# RL6842_IP_SVD register map
Vendor: Realtek
Registers are 32-bit, read-write, reset 0x0 unless marked. A register's access mark holds for its fields unless they carry their own. Offsets are from the block's base; [hi:lo] are bit positions; lines under a group give offsets from that group; {n}, {i} and the like mark numbered series.

## MEMX
Base 0x4100C600
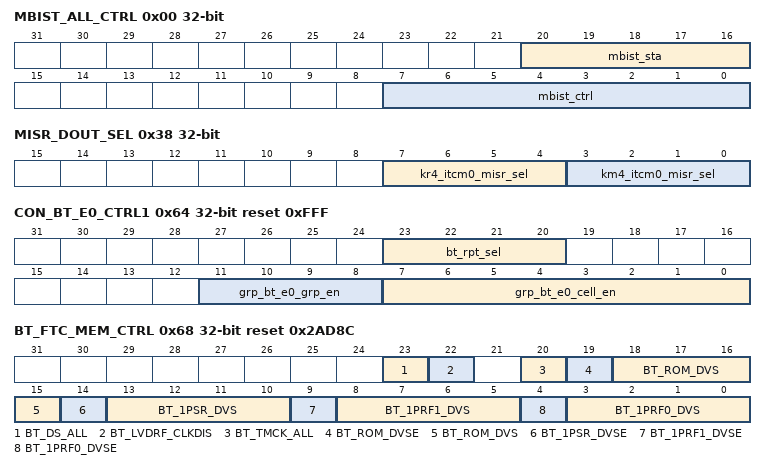
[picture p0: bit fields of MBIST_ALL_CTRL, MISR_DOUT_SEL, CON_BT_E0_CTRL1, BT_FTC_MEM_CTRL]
0x00 MBIST_ALL_CTRL access per field
  [20:16] mbist_sta ro — Total mbist status [16] MBIST DRF_START_PAUSE [17] MBIST NRML_DONE_ALL [18] MBIST NRML_FAIL_ALL [19] MBIST DRF_DONE_ALL [20] MBIST DRF_FAIL_ALL
  [7:0] mbist_ctrl rw — Total mbist control [0] MBIST_CLK_EN_ALL BIS_CLK enable of all system memory groups. [1] MBIST_RSTB_ALL Reset controll mbist circuit of all system memory groups. [3:2]MBIST_MSEL_ALL mbist method selection of all memory groups: 2'b01: enable normal mode mbist 2'b10: enable DRF mode mbist 2'b11: enable normal&DRF mode mbist [4]MBIST_RESUME [5]MBIST_RESUME_PS [6]MBIST_DYN_READ_EN If MBIST_MSEL_ALL[1]=1 & MBIST_DYN_READ_EN=1, run VDDR mode mbist. [7]MBIST_PHYCLK_STOP
0x04 MBIST_DONE_STA0 ro
  [30:0] mbist_done — 30 mbist_group in es003 1 special group bt_e0
0x08 MBIST_START_PAUSE0 ro
  [30:0] mbist_start_pause
0x0C MBIST_NORM_FAIL0 ro
  [31:0] mbist_norm_fail_31_0
0x10 MBIST_NORM_FAIL1 ro
  [31:0] mbist_norm_fail_63_32
0x14 MBIST_NORM_FAIL2 ro
  [23:0] mbist_norm_fail_87_64 — 87 memory block in es003 1 special bt block
0x18 MBIST_DRF_FAIL0 ro
  [31:0] mbist_drf_fail_31_0
0x1C MBIST_DRF_FAIL1 ro
  [31:0] mbist_drf_fail_63_32
0x20 MBIST_DRF_FAIL2 ro
  [23:0] mbist_drf_fail_87_64 — 87 memory block in es003 1 special bt block
0x24 BT_BIST_DONE ro
0x28 BT_BIST_FAIL ro
0x2C BT_BIST_DRF_PASUE ro
  [31:0] bt_bist_drf_pause
0x38 MISR_DOUT_SEL
  [7:4] kr4_itcm0_misr_sel — Used for KR4 itcm rom mbist, select which rom's misr_dataout[63:0] can be read from KR4_ITCM_ROM_MISR_DOUT.
  [3:0] km4_itcm0_misr_sel — Used for KM4 itcm rom mbist, select which rom's misr_dataout[63:0] can be read from KM4_ITCM_ROM_MISR_DOUT.
0x3C MBIST_ROM_MISR0 ro
  [31:0] rom_lspmc_e0_misr_dout_31_0
0x40 MBIST_ROM_MISR1 ro
  [3:0] rom_lspmc_e0_misr_dout_35_32
0x44 MBIST_ROM_MISR2 ro
  [31:0] rom_aonpmc_e0_misr_dout_31_0
0x48 MBIST_ROM_MISR3 ro
  [3:0] rom_aonpmc_e0_misr_dout_35_32
0x4C MBIST_ROM_MISR4 ro
  [31:0] km4_itcm0_rom_misr_dout_31_0
0x50 MBIST_ROM_MISR5 ro
  [31:0] km4_itcm0_rom_misr_dout_63_32
0x54 MBIST_ROM_MISR6 ro
  [31:0] kr4_itcm0_rom_misr_dout_31_0
0x58 MBIST_ROM_MISR7 ro
  [31:0] kr4_itcm0_rom_misr_dout_63_32
0x60 BT_BIST_RPT ro
  [31:0] bt_bist_rpt — bt_rpt_sel 0~3 : read bt_bist_rpt to get BT bist status; bt_rpt_sel 4~15 : read bt_bist_rpt to get BT rom misr_dout;
0x64 CON_BT_E0_CTRL1 reset 0xFFF
  [23:20] bt_rpt_sel — Select which rom's misr_dataout or bist_status of each memory can be read from bt_bist_rpt.
  [11:8] grp_bt_e0_grp_en — Devide all 30 BT memory blocks into 4 groups. grp_bt_e0_grp_en[N]=1 N=0~3: enable mbist of bt_e0 group N.
  [7:0] grp_bt_e0_cell_en — grp_bt_e0_cell_en[M]=1 M=0~7: enable mbist of mem cell M in groups whose grp_bt_e0_grp_en set 1.
0x68 BT_FTC_MEM_CTRL reset 0x2AD8C
  [23] BT_DS_ALL — 1 - All BT memory switch to Deep Sleep mode 0 - Power mode of BT memory are controlled by BTPMC
  [22] BT_LVDRF_CLKDIS
  [20] BT_TMCK_ALL
  [19] BT_ROM_DVSE
  [18:15] BT_ROM_DVS — FSNOU_A_SPNN
  [14] BT_1PSR_DVSE — Not used in Lite
  [13:10] BT_1PSR_DVS — Not used in Lite
  [9] BT_1PRF1_DVSE
  [8:5] BT_1PRF1_DVS — FSNOU_A_SYNL
  [4] BT_1PRF0_DVSE
  [3:0] BT_1PRF0_DVS — FSNOU_A_SYNL
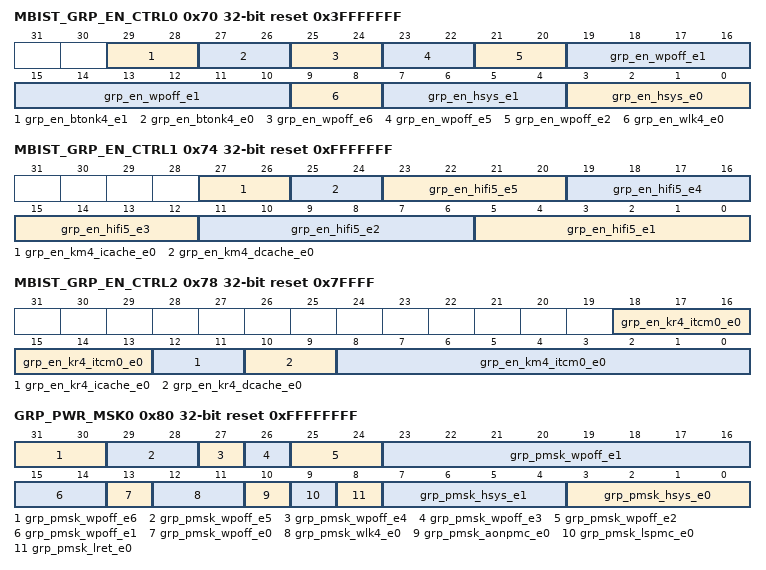
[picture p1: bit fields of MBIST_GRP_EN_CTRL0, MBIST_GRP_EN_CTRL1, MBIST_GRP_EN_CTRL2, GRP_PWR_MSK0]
0x70 MBIST_GRP_EN_CTRL0 reset 0x3FFFFFFF — Used to on-off mbist of a memory group.
  [29:28] grp_en_btonk4_e1
  [27:26] grp_en_btonk4_e0
  [25:24] grp_en_wpoff_e6 — Not used, TPRAM/DPRAM don't need grp_en
  [23:22] grp_en_wpoff_e5 — Not used, TPRAM/DPRAM don't need grp_en
  [21:20] grp_en_wpoff_e2 — Not used, TPRAM/DPRAM don't need grp_en
  [19:10] grp_en_wpoff_e1
  [9:8] grp_en_wlk4_e0
  [7:4] grp_en_hsys_e1
  [3:0] grp_en_hsys_e0
0x74 MBIST_GRP_EN_CTRL1 reset 0xFFFFFFF — Used to on-off mbist in a memory group.
  [27:26] grp_en_km4_icache_e0, [25:24] grp_en_km4_dcache_e0, [23:20] grp_en_hifi5_e5, [19:16] grp_en_hifi5_e4, [15:12] grp_en_hifi5_e3, [11:6] grp_en_hifi5_e2, [5:0] grp_en_hifi5_e1
0x78 MBIST_GRP_EN_CTRL2 reset 0x7FFFF — Used to on-off mbist of memory block in a group.
  [18:13] grp_en_kr4_itcm0_e0, [12:11] grp_en_kr4_icache_e0, [10:9] grp_en_kr4_dcache_e0, [8:0] grp_en_km4_itcm0_e0
0x80 GRP_PWR_MSK0 reset 0xFFFFFFFF
  [31:30] grp_pmsk_wpoff_e6 — WIFI-PMC controlled memory group: bit[N] = 1: power mode of memory block N is controlled by wifi-PMC power signals bit[N] = 0: power port of memory block N is tie0.
  [29:28] grp_pmsk_wpoff_e5 — merged
  [27] grp_pmsk_wpoff_e4 — merged
  [26] grp_pmsk_wpoff_e3 — merged
  [25:24] grp_pmsk_wpoff_e2 — merged
  [23:14] grp_pmsk_wpoff_e1 — merged
  [13] grp_pmsk_wpoff_e0 — merged
  [12:11] grp_pmsk_wlk4_e0
  [10] grp_pmsk_aonpmc_e0
  [9] grp_pmsk_lspmc_e0
  [8] grp_pmsk_lret_e0
  [7:4] grp_pmsk_hsys_e1
  [3:0] grp_pmsk_hsys_e0 — SYSPMC controlled memory groups: bit[N] = 1: power mode of memory block N is controlled by rw_hsys_e0_pwr_slp[2:0]; bit[N] = 0: power mode of memory block N is controlled by rw_hsys_e0_pwr_act[2:0]
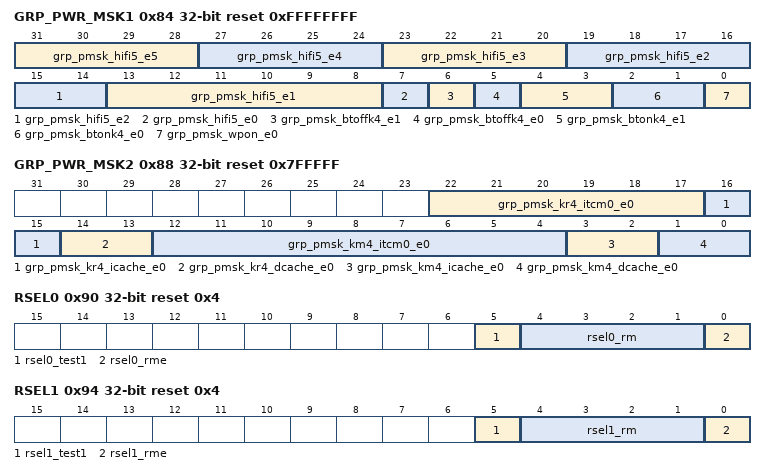
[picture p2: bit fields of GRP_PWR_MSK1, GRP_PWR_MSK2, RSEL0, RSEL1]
0x84 GRP_PWR_MSK1 reset 0xFFFFFFFF
  [31:28] grp_pmsk_hifi5_e5, [27:24] grp_pmsk_hifi5_e4, [23:20] grp_pmsk_hifi5_e3, [19:14] grp_pmsk_hifi5_e2, [13:8] grp_pmsk_hifi5_e1, [7] grp_pmsk_hifi5_e0, [6] grp_pmsk_btoffk4_e1, [5] grp_pmsk_btoffk4_e0, [4:3] grp_pmsk_btonk4_e1, [2:1] grp_pmsk_btonk4_e0, [0] grp_pmsk_wpon_e0
0x88 GRP_PWR_MSK2 reset 0x7FFFFF
  [22:17] grp_pmsk_kr4_itcm0_e0 — CPU cache/rom: bit[N]=1 : power mode of memory block N is controlled by rw_itcm_pwr_act[2:0] bit[N/=0: power port of memory block N is tie0.
  [16:15] grp_pmsk_kr4_icache_e0 — merged
  [14:13] grp_pmsk_kr4_dcache_e0 — merged
  [12:4] grp_pmsk_km4_itcm0_e0 — merged
  [3:2] grp_pmsk_km4_icache_e0 — merged
  [1:0] grp_pmsk_km4_dcache_e0 — merged
0x90 RSEL0 reset 0x4
  [5] rsel0_test1, [4:1] rsel0_rm, [0] rsel0_rme
0x94 RSEL1 reset 0x4
  [5] rsel1_test1
  [4:1] rsel1_rm
  [0] rsel1_rme — SNPS_ULP dummy parameter
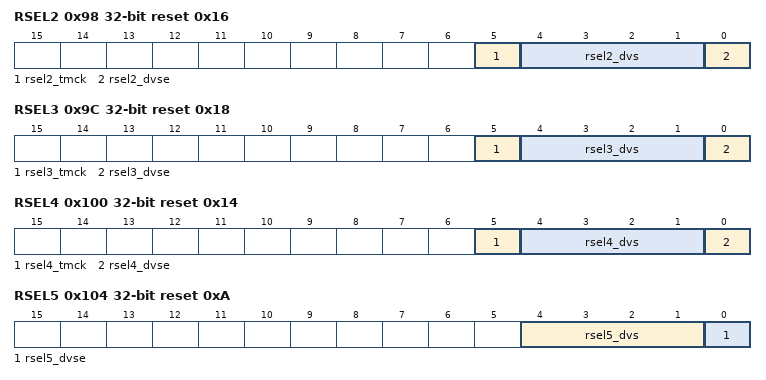
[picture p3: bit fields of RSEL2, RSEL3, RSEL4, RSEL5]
0x98 RSEL2 reset 0x16
  [5] rsel2_tmck, [4:1] rsel2_dvs, [0] rsel2_dvse
0x9C RSEL3 reset 0x18
  [5] rsel3_tmck, [4:1] rsel3_dvs, [0] rsel3_dvse
0x100 RSEL4 reset 0x14
  [5] rsel4_tmck, [4:1] rsel4_dvs, [0] rsel4_dvse
0x104 RSEL5 reset 0xA
  [4:1] rsel5_dvs, [0] rsel5_dvse
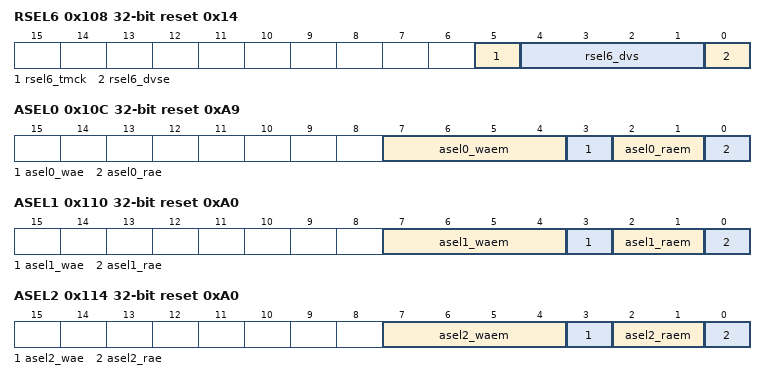
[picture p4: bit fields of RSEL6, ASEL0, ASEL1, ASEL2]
0x108 RSEL6 reset 0x14
  [5] rsel6_tmck
  [4:1] rsel6_dvs
  [0] rsel6_dvse — FTC_ULP dummy parameter
0x10C ASEL0 reset 0xA9
  [7:4] asel0_waem, [3] asel0_wae, [2:1] asel0_raem, [0] asel0_rae
0x110 ASEL1 reset 0xA0
  [7:4] asel1_waem, [3] asel1_wae, [2:1] asel1_raem, [0] asel1_rae
0x114 ASEL2 reset 0xA0
  [7:4] asel2_waem, [3] asel2_wae, [2:1] asel2_raem, [0] asel2_rae
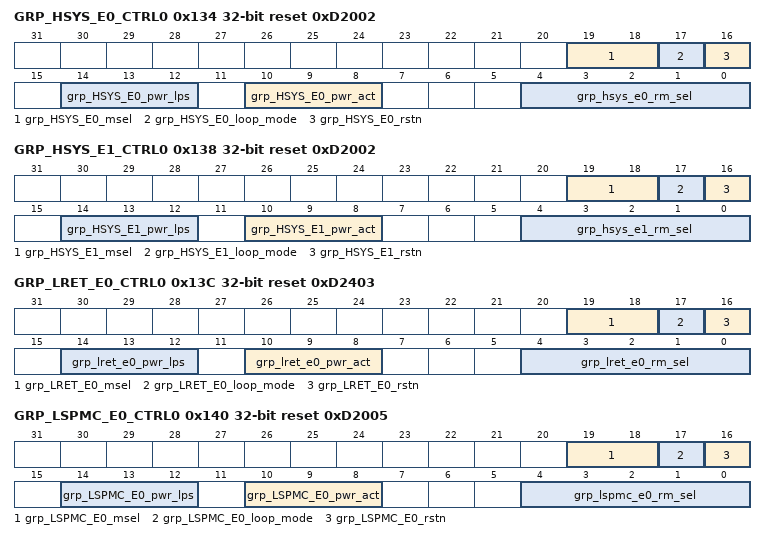
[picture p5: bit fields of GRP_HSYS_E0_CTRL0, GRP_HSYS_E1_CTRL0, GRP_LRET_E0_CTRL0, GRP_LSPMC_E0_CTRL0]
0x134 GRP_HSYS_E0_CTRL0 reset 0xD2002
  [19:18] grp_HSYS_E0_msel — 01 - This memory group can do normal mbist; 10 - This memory group can do DRF mbist; 11 - This memory group can do normal & DRF mbist
  [17] grp_HSYS_E0_loop_mode — 0 - Assist loop mode 1 - Don't assist loop mode
  [16] grp_HSYS_E0_rstn — 0 - Reset mbist circuit of this memory group; 1 - Release mbist circuit of this memory group.
  [14:12] grp_HSYS_E0_pwr_lps — Reserved for grp_HSYS_E0_pwr_lps for memory groups power controlled by SYSPMC. Setted before chip goes to SLEEP.Used to controll power mode of this memory group when chip is in SLEEP. For FTC_ULP mem, pwr_lps[2:0] map to {SLP,RET,NAP}; For SNPS mem, pwr_lps[2:0] map to {SD,DS,LS}. 000 - active 001 - light sleep 010 - deep sleep 100 - shut down
  [10:8] grp_HSYS_E0_pwr_act — Used to controll power mode of this memory group when chip is ACTIVE. For FTC_ULP mem, pwr_act[2:0] map to {SLP,RET,NAP}; For SNPS mem, pwr_act[2:0] map to {SD,DS,LS}. 000 - active 001 - light sleep 010 - deep sleep 100 - shut down
  [4:0] grp_hsys_e0_rm_sel — 1PSR, FSNOU_A_SHNL
0x138 GRP_HSYS_E1_CTRL0 reset 0xD2002
  [19:18] grp_HSYS_E1_msel — 01 - This memory group can do normal mbist; 10 - This memory group can do DRF mbist; 11 - This memory group can do normal & DRF mbist
  [17] grp_HSYS_E1_loop_mode — 0 - Assist loop mode 1 - Don't assist loop mode
  [16] grp_HSYS_E1_rstn — 0 - Reset mbist circuit of this memory group; 1 - Release mbist circuit of this memory group.
  [14:12] grp_HSYS_E1_pwr_lps — Reserved for grp_HSYS_E1_pwr_lps for memory groups power controlled by SYSPMC. Setted before chip goes to SLEEP.Used to controll power mode of this memory group when chip is in SLEEP. For FTC_ULP mem, pwr_lps[2:0] map to {SLP,RET,NAP}; For SNPS mem, pwr_lps[2:0] map to {SD,DS,LS}. 000 - active 001 - light sleep 010 - deep sleep 100 - shut down
  [10:8] grp_HSYS_E1_pwr_act — Used to controll power mode of this memory group when chip is ACTIVE. For FTC_ULP mem, pwr_act[2:0] map to {SLP,RET,NAP}; For SNPS mem, pwr_act[2:0] map to {SD,DS,LS}. 000 - active 001 - light sleep 010 - deep sleep 100 - shut down
  [4:0] grp_hsys_e1_rm_sel — 1PSR, FSNOU_A_SHNL
0x13C GRP_LRET_E0_CTRL0 reset 0xD2403
  [19:18] grp_LRET_E0_msel — 01 - This memory group can do normal mbist; 10 - This memory group can do DRF mbist; 11 - This memory group can do normal & DRF mbist
  [17] grp_LRET_E0_loop_mode — 0 - Assist loop mode 1 - Don't assist loop mode
  [16] grp_LRET_E0_rstn — 0 - Reset mbist circuit of this memory group; 1 - Release mbist circuit of this memory group.
  [14:12] grp_lret_e0_pwr_lps — Reserved for grp_@_pwr_lps for memory groups power controlled by SYSPMC. Setted before chip goes to SLEEP.Used to controll power mode of this memory group when chip is in SLEEP. For FTC_ULP mem, pwr_lps[2:0] map to {SLP,RET,NAP}; For SNPS mem, pwr_lps[2:0] map to {SD,DS,LS}. 100 - active 101 - light sleep 110 - deep sleep 000 - shut down
  [10:8] grp_lret_e0_pwr_act — Used to controll power mode of this memory group when chip is ACTIVE. For FTC_ULP mem, pwr_act[2:0] map to {SLP,RET,NAP}; For SNPS mem, pwr_act[2:0] map to {SD,DS,LS}. 100 - active 101 - light sleep 110 - deep sleep 000 - shut down
  [4:0] grp_lret_e0_rm_sel — 1PRF, FSNOU_A_SYNL
0x140 GRP_LSPMC_E0_CTRL0 reset 0xD2005
  [19:18] grp_LSPMC_E0_msel — 01 - This memory group can do normal mbist; 10 - This memory group can do DRF mbist; 11 - This memory group can do normal & DRF mbist
  [17] grp_LSPMC_E0_loop_mode — 0 - Assist loop mode 1 - Don't assist loop mode
  [16] grp_LSPMC_E0_rstn — 0 - Reset mbist circuit of this memory group; 1 - Release mbist circuit of this memory group.
  [14:12] grp_LSPMC_E0_pwr_lps — Reserved for grp_LSPMC_E0_pwr_lps for memory groups power controlled by SYSPMC. Setted before chip goes to SLEEP.Used to controll power mode of this memory group when chip is in SLEEP. For FTC_ULP mem, pwr_lps[2:0] map to {SLP,RET,NAP}; For SNPS mem, pwr_lps[2:0] map to {SD,DS,LS}. 000 - active 001 - light sleep 010 - deep sleep 100 - shut down
  [10:8] grp_LSPMC_E0_pwr_act — Used to controll power mode of this memory group when chip is ACTIVE. For FTC_ULP mem, pwr_act[2:0] map to {SLP,RET,NAP}; For SNPS mem, pwr_act[2:0] map to {SD,DS,LS}. 000 - active 001 - light sleep 010 - deep sleep 100 - shut down
  [4:0] grp_lspmc_e0_rm_sel — FTC_ULP ROM
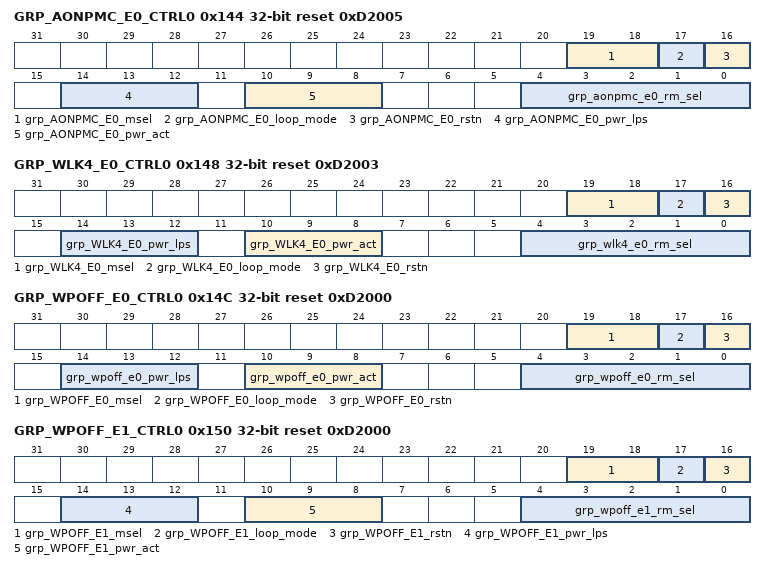
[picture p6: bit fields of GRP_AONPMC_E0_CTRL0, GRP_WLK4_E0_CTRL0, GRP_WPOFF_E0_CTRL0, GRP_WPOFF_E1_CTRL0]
0x144 GRP_AONPMC_E0_CTRL0 reset 0xD2005
  [19:18] grp_AONPMC_E0_msel — 01 - This memory group can do normal mbist; 10 - This memory group can do DRF mbist; 11 - This memory group can do normal & DRF mbist
  [17] grp_AONPMC_E0_loop_mode — 0 - Assist loop mode 1 - Don't assist loop mode
  [16] grp_AONPMC_E0_rstn — 0 - Reset mbist circuit of this memory group; 1 - Release mbist circuit of this memory group.
  [14:12] grp_AONPMC_E0_pwr_lps — Reserved for grp_AONPMC_E0_pwr_lps for memory groups power controlled by SYSPMC. Setted before chip goes to SLEEP.Used to controll power mode of this memory group when chip is in SLEEP. For FTC_ULP mem, pwr_lps[2:0] map to {SLP,RET,NAP}; For SNPS mem, pwr_lps[2:0] map to {SD,DS,LS}. 000 - active 001 - light sleep 010 - deep sleep 100 - shut down
  [10:8] grp_AONPMC_E0_pwr_act — Used to controll power mode of this memory group when chip is ACTIVE. For FTC_ULP mem, pwr_act[2:0] map to {SLP,RET,NAP}; For SNPS mem, pwr_act[2:0] map to {SD,DS,LS}. 000 - active 001 - light sleep 010 - deep sleep 100 - shut down
  [4:0] grp_aonpmc_e0_rm_sel — FTC_ULP ROM
0x148 GRP_WLK4_E0_CTRL0 reset 0xD2003
  [19:18] grp_WLK4_E0_msel — 01 - This memory group can do normal mbist; 10 - This memory group can do DRF mbist; 11 - This memory group can do normal & DRF mbist
  [17] grp_WLK4_E0_loop_mode — 0 - Assist loop mode 1 - Don't assist loop mode
  [16] grp_WLK4_E0_rstn — 0 - Reset mbist circuit of this memory group; 1 - Release mbist circuit of this memory group.
  [14:12] grp_WLK4_E0_pwr_lps — Reserved for grp_WLK4_E0_pwr_lps for memory groups power controlled by SYSPMC. Setted before chip goes to SLEEP.Used to controll power mode of this memory group when chip is in SLEEP. For FTC_ULP mem, pwr_lps[2:0] map to {SLP,RET,NAP}; For SNPS mem, pwr_lps[2:0] map to {SD,DS,LS}. 000 - active 001 - light sleep 010 - deep sleep 100 - shut down
  [10:8] grp_WLK4_E0_pwr_act — Used to controll power mode of this memory group when chip is ACTIVE. For FTC_ULP mem, pwr_act[2:0] map to {SLP,RET,NAP}; For SNPS mem, pwr_act[2:0] map to {SD,DS,LS}. 000 - active 001 - light sleep 010 - deep sleep 100 - shut down
  [4:0] grp_wlk4_e0_rm_sel — 1PRF,FSNOU_A_SYNL
0x14C GRP_WPOFF_E0_CTRL0 reset 0xD2000
  [19:18] grp_WPOFF_E0_msel — 01 - This memory group can do normal mbist; 10 - This memory group can do DRF mbist; 11 - This memory group can do normal & DRF mbist
  [17] grp_WPOFF_E0_loop_mode — 0 - Assist loop mode 1 - Don't assist loop mode
  [16] grp_WPOFF_E0_rstn — 0 - Reset mbist circuit of this memory group; 1 - Release mbist circuit of this memory group.
  [14:12] grp_wpoff_e0_pwr_lps — Used to controll power mode of this memory group when chip is SLEEP. SNPS mem map to {SD,DS,LS}. SNPS_with_PG memory don't assign DS/SD in scan mode
  [10:8] grp_wpoff_e0_pwr_act — Used to controll power mode of this memory group when chip is ACTIVE. SNPS mem map to {SD,DS,LS}. SNPS_with_PG memory don't assign DS/SD in scan mode
  [4:0] grp_wpoff_e0_rm_sel — 1PRF,SNPS
0x150 GRP_WPOFF_E1_CTRL0 reset 0xD2000
  [19:18] grp_WPOFF_E1_msel — 01 - This memory group can do normal mbist; 10 - This memory group can do DRF mbist; 11 - This memory group can do normal & DRF mbist
  [17] grp_WPOFF_E1_loop_mode — 0 - Assist loop mode 1 - Don't assist loop mode
  [16] grp_WPOFF_E1_rstn — 0 - Reset mbist circuit of this memory group; 1 - Release mbist circuit of this memory group.
  [14:12] grp_WPOFF_E1_pwr_lps — Reserved for grp_WPOFF_E1_pwr_lps for memory groups power controlled by SYSPMC. Setted before chip goes to SLEEP.Used to controll power mode of this memory group when chip is in SLEEP. For FTC_ULP mem, pwr_lps[2:0] map to {SLP,RET,NAP}; For SNPS mem, pwr_lps[2:0] map to {SD,DS,LS}. 000 - active 001 - light sleep 010 - deep sleep 100 - shut down
  [10:8] grp_WPOFF_E1_pwr_act — Used to controll power mode of this memory group when chip is ACTIVE. For FTC_ULP mem, pwr_act[2:0] map to {SLP,RET,NAP}; For SNPS mem, pwr_act[2:0] map to {SD,DS,LS}. 000 - active 001 - light sleep 010 - deep sleep 100 - shut down
  [4:0] grp_wpoff_e1_rm_sel — 1PRF,SNPS
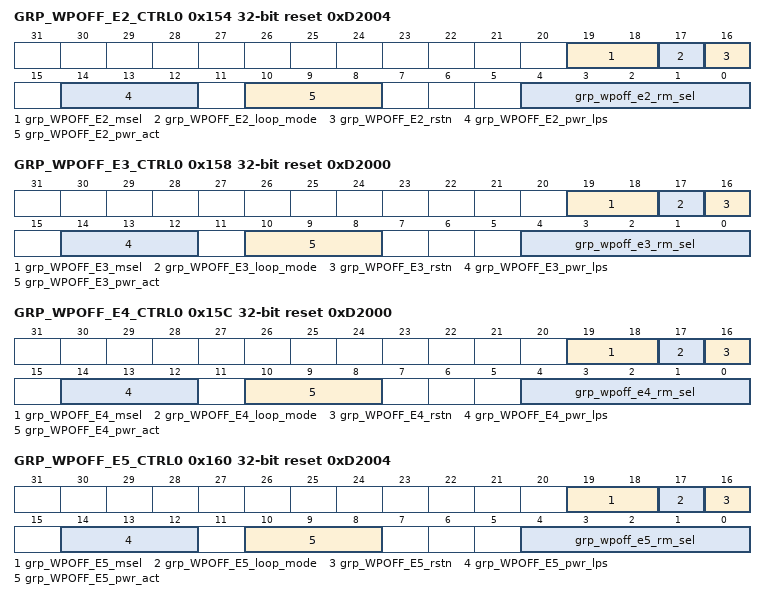
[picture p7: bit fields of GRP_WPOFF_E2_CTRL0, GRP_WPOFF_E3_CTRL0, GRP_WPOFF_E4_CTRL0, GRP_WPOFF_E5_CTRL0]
0x154 GRP_WPOFF_E2_CTRL0 reset 0xD2004
  [19:18] grp_WPOFF_E2_msel — 01 - This memory group can do normal mbist; 10 - This memory group can do DRF mbist; 11 - This memory group can do normal & DRF mbist
  [17] grp_WPOFF_E2_loop_mode — 0 - Assist loop mode 1 - Don't assist loop mode
  [16] grp_WPOFF_E2_rstn — 0 - Reset mbist circuit of this memory group; 1 - Release mbist circuit of this memory group.
  [14:12] grp_WPOFF_E2_pwr_lps — Reserved for grp_WPOFF_E2_pwr_lps for memory groups power controlled by SYSPMC. Setted before chip goes to SLEEP.Used to controll power mode of this memory group when chip is in SLEEP. For FTC_ULP mem, pwr_lps[2:0] map to {SLP,RET,NAP}; For SNPS mem, pwr_lps[2:0] map to {SD,DS,LS}. 000 - active 001 - light sleep 010 - deep sleep 100 - shut down
  [10:8] grp_WPOFF_E2_pwr_act — Used to controll power mode of this memory group when chip is ACTIVE. For FTC_ULP mem, pwr_act[2:0] map to {SLP,RET,NAP}; For SNPS mem, pwr_act[2:0] map to {SD,DS,LS}. 000 - active 001 - light sleep 010 - deep sleep 100 - shut down
  [4:0] grp_wpoff_e2_rm_sel — 2PRF,FSNOU_A_SZNN
0x158 GRP_WPOFF_E3_CTRL0 reset 0xD2000
  [19:18] grp_WPOFF_E3_msel — 01 - This memory group can do normal mbist; 10 - This memory group can do DRF mbist; 11 - This memory group can do normal & DRF mbist
  [17] grp_WPOFF_E3_loop_mode — 0 - Assist loop mode 1 - Don't assist loop mode
  [16] grp_WPOFF_E3_rstn — 0 - Reset mbist circuit of this memory group; 1 - Release mbist circuit of this memory group.
  [14:12] grp_WPOFF_E3_pwr_lps — Reserved for grp_WPOFF_E3_pwr_lps for memory groups power controlled by SYSPMC. Setted before chip goes to SLEEP.Used to controll power mode of this memory group when chip is in SLEEP. For FTC_ULP mem, pwr_lps[2:0] map to {SLP,RET,NAP}; For SNPS mem, pwr_lps[2:0] map to {SD,DS,LS}. 000 - active 001 - light sleep 010 - deep sleep 100 - shut down
  [10:8] grp_WPOFF_E3_pwr_act — Used to controll power mode of this memory group when chip is ACTIVE. For FTC_ULP mem, pwr_act[2:0] map to {SLP,RET,NAP}; For SNPS mem, pwr_act[2:0] map to {SD,DS,LS}. 000 - active 001 - light sleep 010 - deep sleep 100 - shut down
  [4:0] grp_wpoff_e3_rm_sel — 1PRF,SNPS
0x15C GRP_WPOFF_E4_CTRL0 reset 0xD2000
  [19:18] grp_WPOFF_E4_msel — 01 - This memory group can do normal mbist; 10 - This memory group can do DRF mbist; 11 - This memory group can do normal & DRF mbist
  [17] grp_WPOFF_E4_loop_mode — 0 - Assist loop mode 1 - Don't assist loop mode
  [16] grp_WPOFF_E4_rstn — 0 - Reset mbist circuit of this memory group; 1 - Release mbist circuit of this memory group.
  [14:12] grp_WPOFF_E4_pwr_lps — Reserved for grp_WPOFF_E4_pwr_lps for memory groups power controlled by SYSPMC. Setted before chip goes to SLEEP.Used to controll power mode of this memory group when chip is in SLEEP. For FTC_ULP mem, pwr_lps[2:0] map to {SLP,RET,NAP}; For SNPS mem, pwr_lps[2:0] map to {SD,DS,LS}. 000 - active 001 - light sleep 010 - deep sleep 100 - shut down
  [10:8] grp_WPOFF_E4_pwr_act — Used to controll power mode of this memory group when chip is ACTIVE. For FTC_ULP mem, pwr_act[2:0] map to {SLP,RET,NAP}; For SNPS mem, pwr_act[2:0] map to {SD,DS,LS}. 000 - active 001 - light sleep 010 - deep sleep 100 - shut down
  [4:0] grp_wpoff_e4_rm_sel — 1PRF,SNPS
0x160 GRP_WPOFF_E5_CTRL0 reset 0xD2004
  [19:18] grp_WPOFF_E5_msel — 01 - This memory group can do normal mbist; 10 - This memory group can do DRF mbist; 11 - This memory group can do normal & DRF mbist
  [17] grp_WPOFF_E5_loop_mode — 0 - Assist loop mode 1 - Don't assist loop mode
  [16] grp_WPOFF_E5_rstn — 0 - Reset mbist circuit of this memory group; 1 - Release mbist circuit of this memory group.
  [14:12] grp_WPOFF_E5_pwr_lps — Reserved for grp_WPOFF_E5_pwr_lps for memory groups power controlled by SYSPMC. Setted before chip goes to SLEEP.Used to controll power mode of this memory group when chip is in SLEEP. For FTC_ULP mem, pwr_lps[2:0] map to {SLP,RET,NAP}; For SNPS mem, pwr_lps[2:0] map to {SD,DS,LS}. 000 - active 001 - light sleep 010 - deep sleep 100 - shut down
  [10:8] grp_WPOFF_E5_pwr_act — Used to controll power mode of this memory group when chip is ACTIVE. For FTC_ULP mem, pwr_act[2:0] map to {SLP,RET,NAP}; For SNPS mem, pwr_act[2:0] map to {SD,DS,LS}. 000 - active 001 - light sleep 010 - deep sleep 100 - shut down
  [4:0] grp_wpoff_e5_rm_sel — 2PRF,FSNOU_A_SZNL
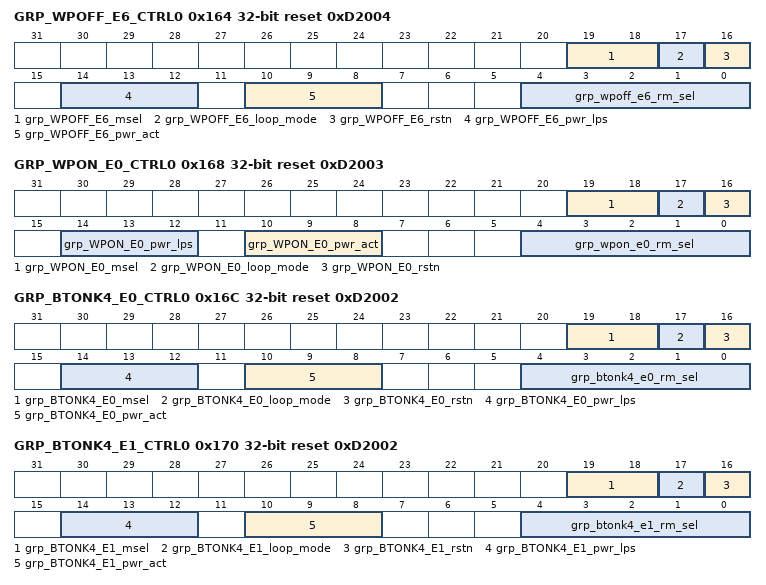
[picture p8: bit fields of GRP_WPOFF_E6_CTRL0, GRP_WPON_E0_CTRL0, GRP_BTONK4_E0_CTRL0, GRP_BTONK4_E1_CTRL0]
0x164 GRP_WPOFF_E6_CTRL0 reset 0xD2004
  [19:18] grp_WPOFF_E6_msel — 01 - This memory group can do normal mbist; 10 - This memory group can do DRF mbist; 11 - This memory group can do normal & DRF mbist
  [17] grp_WPOFF_E6_loop_mode — 0 - Assist loop mode 1 - Don't assist loop mode
  [16] grp_WPOFF_E6_rstn — 0 - Reset mbist circuit of this memory group; 1 - Release mbist circuit of this memory group.
  [14:12] grp_WPOFF_E6_pwr_lps — Reserved for grp_WPOFF_E6_pwr_lps for memory groups power controlled by SYSPMC. Setted before chip goes to SLEEP.Used to controll power mode of this memory group when chip is in SLEEP. For FTC_ULP mem, pwr_lps[2:0] map to {SLP,RET,NAP}; For SNPS mem, pwr_lps[2:0] map to {SD,DS,LS}. 000 - active 001 - light sleep 010 - deep sleep 100 - shut down
  [10:8] grp_WPOFF_E6_pwr_act — Used to controll power mode of this memory group when chip is ACTIVE. For FTC_ULP mem, pwr_act[2:0] map to {SLP,RET,NAP}; For SNPS mem, pwr_act[2:0] map to {SD,DS,LS}. 000 - active 001 - light sleep 010 - deep sleep 100 - shut down
  [4:0] grp_wpoff_e6_rm_sel — 2PRF,FSNOU_A_SZNL
0x168 GRP_WPON_E0_CTRL0 reset 0xD2003
  [19:18] grp_WPON_E0_msel — 01 - This memory group can do normal mbist; 10 - This memory group can do DRF mbist; 11 - This memory group can do normal & DRF mbist
  [17] grp_WPON_E0_loop_mode — 0 - Assist loop mode 1 - Don't assist loop mode
  [16] grp_WPON_E0_rstn — 0 - Reset mbist circuit of this memory group; 1 - Release mbist circuit of this memory group.
  [14:12] grp_WPON_E0_pwr_lps — Reserved for grp_WPON_E0_pwr_lps for memory groups power controlled by SYSPMC. Setted before chip goes to SLEEP.Used to controll power mode of this memory group when chip is in SLEEP. For FTC_ULP mem, pwr_lps[2:0] map to {SLP,RET,NAP}; For SNPS mem, pwr_lps[2:0] map to {SD,DS,LS}. 000 - active 001 - light sleep 010 - deep sleep 100 - shut down
  [10:8] grp_WPON_E0_pwr_act — Used to controll power mode of this memory group when chip is ACTIVE. For FTC_ULP mem, pwr_act[2:0] map to {SLP,RET,NAP}; For SNPS mem, pwr_act[2:0] map to {SD,DS,LS}. 000 - active 001 - light sleep 010 - deep sleep 100 - shut down
  [4:0] grp_wpon_e0_rm_sel — 1prf,FSNOU_A_SYNL
0x16C GRP_BTONK4_E0_CTRL0 reset 0xD2002
  [19:18] grp_BTONK4_E0_msel — 01 - This memory group can do normal mbist; 10 - This memory group can do DRF mbist; 11 - This memory group can do normal & DRF mbist
  [17] grp_BTONK4_E0_loop_mode — 0 - Assist loop mode 1 - Don't assist loop mode
  [16] grp_BTONK4_E0_rstn — 0 - Reset mbist circuit of this memory group; 1 - Release mbist circuit of this memory group.
  [14:12] grp_BTONK4_E0_pwr_lps — Reserved for grp_BTONK4_E0_pwr_lps for memory groups power controlled by SYSPMC. Setted before chip goes to SLEEP.Used to controll power mode of this memory group when chip is in SLEEP. For FTC_ULP mem, pwr_lps[2:0] map to {SLP,RET,NAP}; For SNPS mem, pwr_lps[2:0] map to {SD,DS,LS}. 000 - active 001 - light sleep 010 - deep sleep 100 - shut down
  [10:8] grp_BTONK4_E0_pwr_act — Used to controll power mode of this memory group when chip is ACTIVE. For FTC_ULP mem, pwr_act[2:0] map to {SLP,RET,NAP}; For SNPS mem, pwr_act[2:0] map to {SD,DS,LS}. 000 - active 001 - light sleep 010 - deep sleep 100 - shut down
  [4:0] grp_btonk4_e0_rm_sel — 1PSR,FSNOU_A_SHNL
0x170 GRP_BTONK4_E1_CTRL0 reset 0xD2002
  [19:18] grp_BTONK4_E1_msel — 01 - This memory group can do normal mbist; 10 - This memory group can do DRF mbist; 11 - This memory group can do normal & DRF mbist
  [17] grp_BTONK4_E1_loop_mode — 0 - Assist loop mode 1 - Don't assist loop mode
  [16] grp_BTONK4_E1_rstn — 0 - Reset mbist circuit of this memory group; 1 - Release mbist circuit of this memory group.
  [14:12] grp_BTONK4_E1_pwr_lps — Reserved for grp_BTONK4_E1_pwr_lps for memory groups power controlled by SYSPMC. Setted before chip goes to SLEEP.Used to controll power mode of this memory group when chip is in SLEEP. For FTC_ULP mem, pwr_lps[2:0] map to {SLP,RET,NAP}; For SNPS mem, pwr_lps[2:0] map to {SD,DS,LS}. 000 - active 001 - light sleep 010 - deep sleep 100 - shut down
  [10:8] grp_BTONK4_E1_pwr_act — Used to controll power mode of this memory group when chip is ACTIVE. For FTC_ULP mem, pwr_act[2:0] map to {SLP,RET,NAP}; For SNPS mem, pwr_act[2:0] map to {SD,DS,LS}. 000 - active 001 - light sleep 010 - deep sleep 100 - shut down
  [4:0] grp_btonk4_e1_rm_sel — 1PSR,FSNOU_A_SHNL
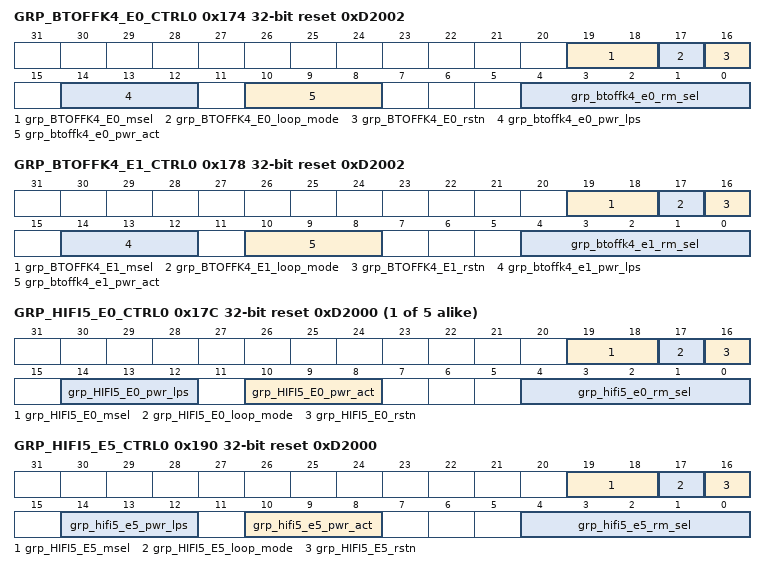
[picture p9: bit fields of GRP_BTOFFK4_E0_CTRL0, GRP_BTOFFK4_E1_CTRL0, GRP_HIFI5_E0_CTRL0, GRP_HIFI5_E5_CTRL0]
0x174 GRP_BTOFFK4_E0_CTRL0 reset 0xD2002
  [19:18] grp_BTOFFK4_E0_msel — 01 - This memory group can do normal mbist; 10 - This memory group can do DRF mbist; 11 - This memory group can do normal & DRF mbist
  [17] grp_BTOFFK4_E0_loop_mode — 0 - Assist loop mode 1 - Don't assist loop mode
  [16] grp_BTOFFK4_E0_rstn — 0 - Reset mbist circuit of this memory group; 1 - Release mbist circuit of this memory group.
  [14:12] grp_btoffk4_e0_pwr_lps — Reserved for grp_@_pwr_lps for memory groups power controlled by SYSPMC. Setted before chip goes to SLEEP.Used to controll power mode of this memory group when chip is in SLEEP. For FTC_ULP mem, pwr_lps[2:0] map to {SLP,RET,NAP}; For SNPS mem, pwr_lps[2:0] map to {SD,DS,LS}. 100 - active 101 - light sleep 110 - deep sleep 000 - shut down
  [10:8] grp_btoffk4_e0_pwr_act — Used to controll power mode of this memory group when chip is ACTIVE. For FTC_ULP mem, pwr_act[2:0] map to {SLP,RET,NAP}; For SNPS mem, pwr_act[2:0] map to {SD,DS,LS}. 100 - active 101 - light sleep 110 - deep sleep 000 - shut down
  [4:0] grp_btoffk4_e0_rm_sel — 1PSR,FSNOU_A_SHNL
0x178 GRP_BTOFFK4_E1_CTRL0 reset 0xD2002
  [19:18] grp_BTOFFK4_E1_msel — 01 - This memory group can do normal mbist; 10 - This memory group can do DRF mbist; 11 - This memory group can do normal & DRF mbist
  [17] grp_BTOFFK4_E1_loop_mode — 0 - Assist loop mode 1 - Don't assist loop mode
  [16] grp_BTOFFK4_E1_rstn — 0 - Reset mbist circuit of this memory group; 1 - Release mbist circuit of this memory group.
  [14:12] grp_btoffk4_e1_pwr_lps — Reserved for grp_@_pwr_lps for memory groups power controlled by SYSPMC. Setted before chip goes to SLEEP.Used to controll power mode of this memory group when chip is in SLEEP. For FTC_ULP mem, pwr_lps[2:0] map to {SLP,RET,NAP}; For SNPS mem, pwr_lps[2:0] map to {SD,DS,LS}. 100 - active 101 - light sleep 110 - deep sleep 000 - shut down
  [10:8] grp_btoffk4_e1_pwr_act — Used to controll power mode of this memory group when chip is ACTIVE. For FTC_ULP mem, pwr_act[2:0] map to {SLP,RET,NAP}; For SNPS mem, pwr_act[2:0] map to {SD,DS,LS}. 100 - active 101 - light sleep 110 - deep sleep 000 - shut down
  [4:0] grp_btoffk4_e1_rm_sel — 1PSR,FSNOU_A_SHNL
{0x17C+4i} GRP_HIFI5_E{i}_CTRL0 reset 0xD2000 (i=0..4)
  [19:18] grp_HIFI5_E{i}_msel — 01 - This memory group can do normal mbist; 10 - This memory group can do DRF mbist; 11 - This memory group can do normal & DRF mbist
  [17] grp_HIFI5_E{i}_loop_mode — 0 - Assist loop mode 1 - Don't assist loop mode
  [16] grp_HIFI5_E{i}_rstn — 0 - Reset mbist circuit of this memory group; 1 - Release mbist circuit of this memory group.
  [14:12] grp_HIFI5_E{i}_pwr_lps — Reserved for grp_HIFI5_E{i}_pwr_lps for memory groups power controlled by SYSPMC. Setted before chip goes to SLEEP.Used to controll power mode of this memory group when chip is in SLEEP. For FTC_ULP mem, pwr_lps[2:0] map to {SLP,RET,NAP}; For SNPS mem, pwr_lps[2:0] map to {SD,DS,LS}. 000 - active 001 - light sleep 010 - deep sleep 100 - shut down
  [10:8] grp_HIFI5_E{i}_pwr_act — Used to controll power mode of this memory group when chip is ACTIVE. For FTC_ULP mem, pwr_act[2:0] map to {SLP,RET,NAP}; For SNPS mem, pwr_act[2:0] map to {SD,DS,LS}. 000 - active 001 - light sleep 010 - deep sleep 100 - shut down
  [4:0] grp_hifi5_e{i}_rm_sel — SNPS
0x190 GRP_HIFI5_E5_CTRL0 reset 0xD2000
  [19:18] grp_HIFI5_E5_msel — 01 - This memory group can do normal mbist; 10 - This memory group can do DRF mbist; 11 - This memory group can do normal & DRF mbist
  [17] grp_HIFI5_E5_loop_mode — 0 - Assist loop mode 1 - Don't assist loop mode
  [16] grp_HIFI5_E5_rstn — 0 - Reset mbist circuit of this memory group; 1 - Release mbist circuit of this memory group.
  [14:12] grp_hifi5_e5_pwr_lps — Used to controll power mode of this memory group when chip is SLEEP. SNPS mem map to {SD,DS,LS}. SNPS_with_PG memory don't assign DS/SD in scan mode
  [10:8] grp_hifi5_e5_pwr_act — Used to controll power mode of this memory group when chip is ACTIVE. SNPS mem map to {SD,DS,LS}. SNPS_with_PG memory don't assign DS/SD in scan mode
  [4:0] grp_hifi5_e5_rm_sel — SNPS
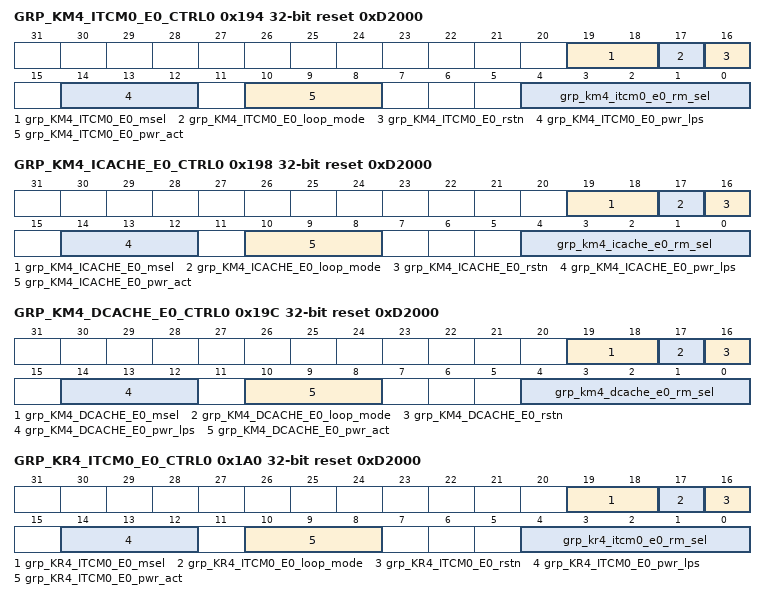
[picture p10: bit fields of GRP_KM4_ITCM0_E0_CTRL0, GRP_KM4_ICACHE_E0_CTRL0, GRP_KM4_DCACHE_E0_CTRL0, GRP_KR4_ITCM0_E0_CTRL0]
0x194 GRP_KM4_ITCM0_E0_CTRL0 reset 0xD2000
  [19:18] grp_KM4_ITCM0_E0_msel — 01 - This memory group can do normal mbist; 10 - This memory group can do DRF mbist; 11 - This memory group can do normal & DRF mbist
  [17] grp_KM4_ITCM0_E0_loop_mode — 0 - Assist loop mode 1 - Don't assist loop mode
  [16] grp_KM4_ITCM0_E0_rstn — 0 - Reset mbist circuit of this memory group; 1 - Release mbist circuit of this memory group.
  [14:12] grp_KM4_ITCM0_E0_pwr_lps — Reserved for grp_KM4_ITCM0_E0_pwr_lps for memory groups power controlled by SYSPMC. Setted before chip goes to SLEEP.Used to controll power mode of this memory group when chip is in SLEEP. For FTC_ULP mem, pwr_lps[2:0] map to {SLP,RET,NAP}; For SNPS mem, pwr_lps[2:0] map to {SD,DS,LS}. 000 - active 001 - light sleep 010 - deep sleep 100 - shut down
  [10:8] grp_KM4_ITCM0_E0_pwr_act — Used to controll power mode of this memory group when chip is ACTIVE. For FTC_ULP mem, pwr_act[2:0] map to {SLP,RET,NAP}; For SNPS mem, pwr_act[2:0] map to {SD,DS,LS}. 000 - active 001 - light sleep 010 - deep sleep 100 - shut down
  [4:0] grp_km4_itcm0_e0_rm_sel — SNPS
0x198 GRP_KM4_ICACHE_E0_CTRL0 reset 0xD2000
  [19:18] grp_KM4_ICACHE_E0_msel — 01 - This memory group can do normal mbist; 10 - This memory group can do DRF mbist; 11 - This memory group can do normal & DRF mbist
  [17] grp_KM4_ICACHE_E0_loop_mode — 0 - Assist loop mode 1 - Don't assist loop mode
  [16] grp_KM4_ICACHE_E0_rstn — 0 - Reset mbist circuit of this memory group; 1 - Release mbist circuit of this memory group.
  [14:12] grp_KM4_ICACHE_E0_pwr_lps — Reserved for grp_KM4_ICACHE_E0_pwr_lps for memory groups power controlled by SYSPMC. Setted before chip goes to SLEEP.Used to controll power mode of this memory group when chip is in SLEEP. For FTC_ULP mem, pwr_lps[2:0] map to {SLP,RET,NAP}; For SNPS mem, pwr_lps[2:0] map to {SD,DS,LS}. 000 - active 001 - light sleep 010 - deep sleep 100 - shut down
  [10:8] grp_KM4_ICACHE_E0_pwr_act — Used to controll power mode of this memory group when chip is ACTIVE. For FTC_ULP mem, pwr_act[2:0] map to {SLP,RET,NAP}; For SNPS mem, pwr_act[2:0] map to {SD,DS,LS}. 000 - active 001 - light sleep 010 - deep sleep 100 - shut down
  [4:0] grp_km4_icache_e0_rm_sel — SNPS
0x19C GRP_KM4_DCACHE_E0_CTRL0 reset 0xD2000
  [19:18] grp_KM4_DCACHE_E0_msel — 01 - This memory group can do normal mbist; 10 - This memory group can do DRF mbist; 11 - This memory group can do normal & DRF mbist
  [17] grp_KM4_DCACHE_E0_loop_mode — 0 - Assist loop mode 1 - Don't assist loop mode
  [16] grp_KM4_DCACHE_E0_rstn — 0 - Reset mbist circuit of this memory group; 1 - Release mbist circuit of this memory group.
  [14:12] grp_KM4_DCACHE_E0_pwr_lps — Reserved for grp_KM4_DCACHE_E0_pwr_lps for memory groups power controlled by SYSPMC. Setted before chip goes to SLEEP.Used to controll power mode of this memory group when chip is in SLEEP. For FTC_ULP mem, pwr_lps[2:0] map to {SLP,RET,NAP}; For SNPS mem, pwr_lps[2:0] map to {SD,DS,LS}. 000 - active 001 - light sleep 010 - deep sleep 100 - shut down
  [10:8] grp_KM4_DCACHE_E0_pwr_act — Used to controll power mode of this memory group when chip is ACTIVE. For FTC_ULP mem, pwr_act[2:0] map to {SLP,RET,NAP}; For SNPS mem, pwr_act[2:0] map to {SD,DS,LS}. 000 - active 001 - light sleep 010 - deep sleep 100 - shut down
  [4:0] grp_km4_dcache_e0_rm_sel — SNPS
0x1A0 GRP_KR4_ITCM0_E0_CTRL0 reset 0xD2000
  [19:18] grp_KR4_ITCM0_E0_msel — 01 - This memory group can do normal mbist; 10 - This memory group can do DRF mbist; 11 - This memory group can do normal & DRF mbist
  [17] grp_KR4_ITCM0_E0_loop_mode — 0 - Assist loop mode 1 - Don't assist loop mode
  [16] grp_KR4_ITCM0_E0_rstn — 0 - Reset mbist circuit of this memory group; 1 - Release mbist circuit of this memory group.
  [14:12] grp_KR4_ITCM0_E0_pwr_lps — Reserved for grp_KR4_ITCM0_E0_pwr_lps for memory groups power controlled by SYSPMC. Setted before chip goes to SLEEP.Used to controll power mode of this memory group when chip is in SLEEP. For FTC_ULP mem, pwr_lps[2:0] map to {SLP,RET,NAP}; For SNPS mem, pwr_lps[2:0] map to {SD,DS,LS}. 000 - active 001 - light sleep 010 - deep sleep 100 - shut down
  [10:8] grp_KR4_ITCM0_E0_pwr_act — Used to controll power mode of this memory group when chip is ACTIVE. For FTC_ULP mem, pwr_act[2:0] map to {SLP,RET,NAP}; For SNPS mem, pwr_act[2:0] map to {SD,DS,LS}. 000 - active 001 - light sleep 010 - deep sleep 100 - shut down
  [4:0] grp_kr4_itcm0_e0_rm_sel — SNPS
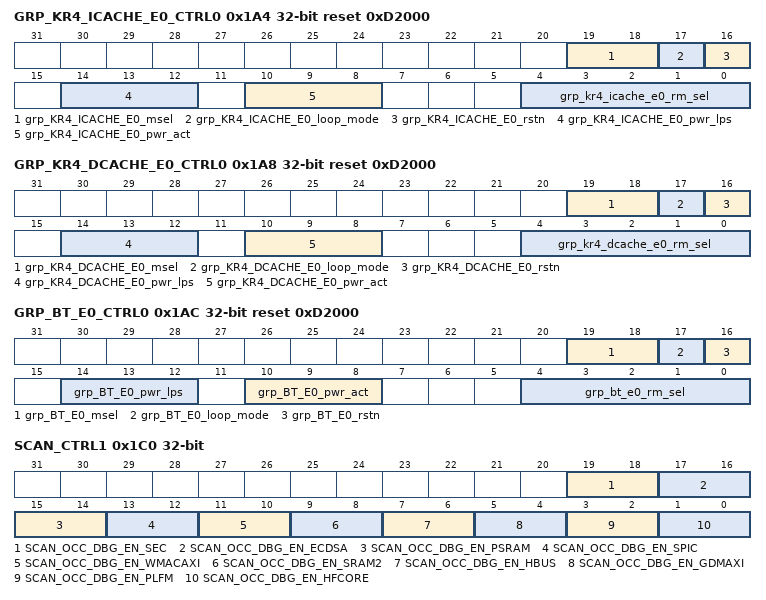
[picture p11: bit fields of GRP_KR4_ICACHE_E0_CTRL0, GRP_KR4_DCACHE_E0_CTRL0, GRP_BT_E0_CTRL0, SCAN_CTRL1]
0x1A4 GRP_KR4_ICACHE_E0_CTRL0 reset 0xD2000
  [19:18] grp_KR4_ICACHE_E0_msel — 01 - This memory group can do normal mbist; 10 - This memory group can do DRF mbist; 11 - This memory group can do normal & DRF mbist
  [17] grp_KR4_ICACHE_E0_loop_mode — 0 - Assist loop mode 1 - Don't assist loop mode
  [16] grp_KR4_ICACHE_E0_rstn — 0 - Reset mbist circuit of this memory group; 1 - Release mbist circuit of this memory group.
  [14:12] grp_KR4_ICACHE_E0_pwr_lps — Reserved for grp_KR4_ICACHE_E0_pwr_lps for memory groups power controlled by SYSPMC. Setted before chip goes to SLEEP.Used to controll power mode of this memory group when chip is in SLEEP. For FTC_ULP mem, pwr_lps[2:0] map to {SLP,RET,NAP}; For SNPS mem, pwr_lps[2:0] map to {SD,DS,LS}. 000 - active 001 - light sleep 010 - deep sleep 100 - shut down
  [10:8] grp_KR4_ICACHE_E0_pwr_act — Used to controll power mode of this memory group when chip is ACTIVE. For FTC_ULP mem, pwr_act[2:0] map to {SLP,RET,NAP}; For SNPS mem, pwr_act[2:0] map to {SD,DS,LS}. 000 - active 001 - light sleep 010 - deep sleep 100 - shut down
  [4:0] grp_kr4_icache_e0_rm_sel — SNPS
0x1A8 GRP_KR4_DCACHE_E0_CTRL0 reset 0xD2000
  [19:18] grp_KR4_DCACHE_E0_msel — 01 - This memory group can do normal mbist; 10 - This memory group can do DRF mbist; 11 - This memory group can do normal & DRF mbist
  [17] grp_KR4_DCACHE_E0_loop_mode — 0 - Assist loop mode 1 - Don't assist loop mode
  [16] grp_KR4_DCACHE_E0_rstn — 0 - Reset mbist circuit of this memory group; 1 - Release mbist circuit of this memory group.
  [14:12] grp_KR4_DCACHE_E0_pwr_lps — Reserved for grp_KR4_DCACHE_E0_pwr_lps for memory groups power controlled by SYSPMC. Setted before chip goes to SLEEP.Used to controll power mode of this memory group when chip is in SLEEP. For FTC_ULP mem, pwr_lps[2:0] map to {SLP,RET,NAP}; For SNPS mem, pwr_lps[2:0] map to {SD,DS,LS}. 000 - active 001 - light sleep 010 - deep sleep 100 - shut down
  [10:8] grp_KR4_DCACHE_E0_pwr_act — Used to controll power mode of this memory group when chip is ACTIVE. For FTC_ULP mem, pwr_act[2:0] map to {SLP,RET,NAP}; For SNPS mem, pwr_act[2:0] map to {SD,DS,LS}. 000 - active 001 - light sleep 010 - deep sleep 100 - shut down
  [4:0] grp_kr4_dcache_e0_rm_sel — SNPS
0x1AC GRP_BT_E0_CTRL0 reset 0xD2000
  [19:18] grp_BT_E0_msel — 01 - This memory group can do normal mbist; 10 - This memory group can do DRF mbist; 11 - This memory group can do normal & DRF mbist
  [17] grp_BT_E0_loop_mode — 0 - Assist loop mode 1 - Don't assist loop mode
  [16] grp_BT_E0_rstn — 0 - Reset mbist circuit of this memory group; 1 - Release mbist circuit of this memory group.
  [14:12] grp_BT_E0_pwr_lps — Reserved for grp_BT_E0_pwr_lps for memory groups power controlled by SYSPMC. Setted before chip goes to SLEEP.Used to controll power mode of this memory group when chip is in SLEEP. For FTC_ULP mem, pwr_lps[2:0] map to {SLP,RET,NAP}; For SNPS mem, pwr_lps[2:0] map to {SD,DS,LS}. 000 - active 001 - light sleep 010 - deep sleep 100 - shut down
  [10:8] grp_BT_E0_pwr_act — Used to controll power mode of this memory group when chip is ACTIVE. For FTC_ULP mem, pwr_act[2:0] map to {SLP,RET,NAP}; For SNPS mem, pwr_act[2:0] map to {SD,DS,LS}. 000 - active 001 - light sleep 010 - deep sleep 100 - shut down
  [4:0] grp_bt_e0_rm_sel — special group
0x1C0 SCAN_CTRL1
  [19:18] SCAN_OCC_DBG_EN_SEC
  [17:16] SCAN_OCC_DBG_EN_ECDSA
  [15:14] SCAN_OCC_DBG_EN_PSRAM
  [13:12] SCAN_OCC_DBG_EN_SPIC
  [11:10] SCAN_OCC_DBG_EN_WMACAXI
  [9:8] SCAN_OCC_DBG_EN_SRAM2
  [7:6] SCAN_OCC_DBG_EN_HBUS
  [5:4] SCAN_OCC_DBG_EN_GDMAXI
  [3:2] SCAN_OCC_DBG_EN_PLFM
  [1:0] SCAN_OCC_DBG_EN_HFCORE — scan occ dbg en hifi core
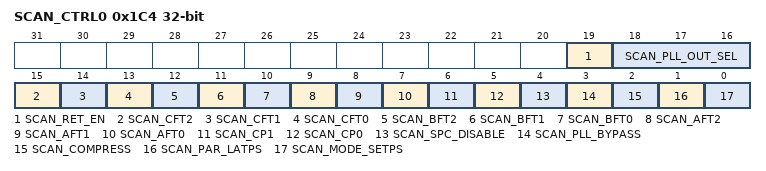
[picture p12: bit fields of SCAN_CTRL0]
0x1C4 SCAN_CTRL0 access per field
  [19] SCAN_RET_EN rw — scan retention test enable
  [18:16] SCAN_PLL_OUT_SEL rw
  [15] SCAN_CFT2 rw — scan QFN88 package ft mode2
  [14] SCAN_CFT1 rw — scan QFN88 package ft mode1
  [13] SCAN_CFT0 rw — scan QFN88 package ft mode0
  [12] SCAN_BFT2 rw — scan QFN144 NON-MCM package ft mode2
  [11] SCAN_BFT1 rw — scan QFN144 NON-MCM package ft mode1
  [10] SCAN_BFT0 rw — scan QFN144 NON-MCM package ft mode0
  [9] SCAN_AFT2 rw — scan QFN144 MCM package ft mode2
  [8] SCAN_AFT1 rw — scan QFN144 MCM package ft mode1
  [7] SCAN_AFT0 rw — scan QFN144 MCM package ft mode0
  [6] SCAN_CP1 rw — scan cp mode1
  [5] SCAN_CP0 rw — scan cp mode0
  [4] SCAN_SPC_DISABLE rw
  [3] SCAN_PLL_BYPASS rw
  [2] SCAN_COMPRESS rw
  [1] SCAN_PAR_LATPS rw — Used as scan latch enable bit . If want to change scan par from func setting , set this bit to 1 first , then write func register will also effect scan shadow register .
  [0] SCAN_MODE_SETPS wo — scan mode pulse
0x1F4 REG_DUMMY_1F4
  [31:0] dummy — HW used only , these are for reserved.
0x1F8 REG_DUMMY_1F8 reset 0xFFFFFFFF
  [31:0] dummy — HW used only , these are for reserved.
0x1FC REG_DUMMY_1FC
  [31:0] dummy — HW used only , these are for reserved.
